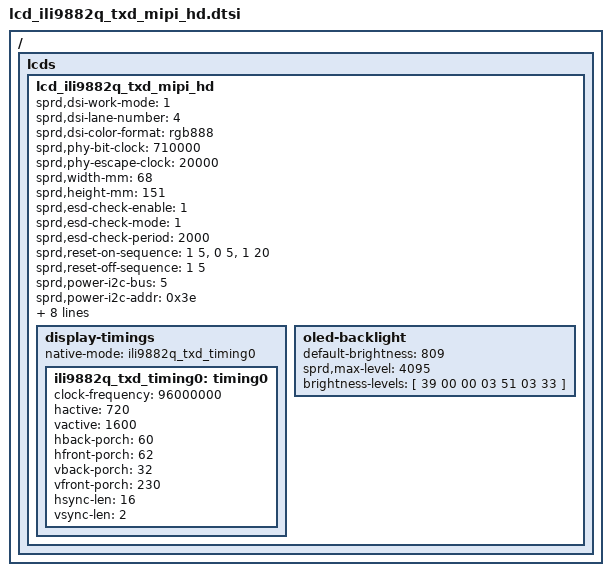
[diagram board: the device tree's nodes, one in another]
/ {
	fragment {
		target-path = "/";
		__overlay__ {
			lcds {
				lcd_ili9882q_txd_mipi_hd: lcd_ili9882q_txd_mipi_hd {
					sprd,dsi-work-mode = <1>; /* video burst mode*/
					sprd,dsi-lane-number = <4>;
					sprd,dsi-color-format = "rgb888";

					sprd,phy-bit-clock = <710000>;	/* kbps */
					sprd,phy-escape-clock = <20000>;/* kHz */

					sprd,width-mm = <68>;
					sprd,height-mm = <151>;

					sprd,esd-check-enable = <1>;
					sprd,esd-check-mode = <1>; /*1TE 0reg */
					sprd,esd-check-period = <2000>;
					/* sprd,esd-check-register = <0x0A>; */
					/* sprd,esd-check-value = <0x9C>; */

					sprd,reset-on-sequence = <1 5>, <0 5>, <1 20>;
					sprd,reset-off-sequence = <1 5>;

					sprd,power-i2c-bus = <5>;
					sprd,power-i2c-addr = <0x3e>;
					sprd,power-i2c-reg = [00 01 03];
					sprd,power-i2c-val = [14 14 03];

					/* sprd,use-dcs-write;*/
					sprd,initial-command = [
						39 00 00 04 FF 98 82 01
						39 00 00 02 00 44
						39 00 00 02 01 13
						39 00 00 02 02 10
						39 00 00 02 03 20
						39 00 00 02 04 CA
						39 00 00 02 05 13
						39 00 00 02 06 10
						39 00 00 02 07 20
						39 00 00 02 08 82
						39 00 00 02 09 09
						39 00 00 02 0a b3
						39 00 00 02 0b 00
						39 00 00 02 0c 17
						39 00 00 02 0d 17
						39 00 00 02 0e 04
						39 00 00 02 0f 04
						39 00 00 02 10 0A
						39 00 00 02 11 0A
						39 00 00 02 12 09
						39 00 00 02 1E 0A
						39 00 00 02 1F 0A
						39 00 00 02 16 82
						39 00 00 02 17 09
						39 00 00 02 18 33
						39 00 00 02 19 00
						39 00 00 02 1a 17
						39 00 00 02 1b 17
						39 00 00 02 1c 04
						39 00 00 02 1d 04
						39 00 00 02 20 09
						39 00 00 02 24 02
						39 00 00 02 25 0b
						39 00 00 02 26 10
						39 00 00 02 27 20
						39 00 00 02 2c 34
						39 00 00 02 31 07
						39 00 00 02 32 2a
						39 00 00 02 33 2a
						39 00 00 02 34 0D
						39 00 00 02 35 28
						39 00 00 02 36 29
						39 00 00 02 37 11
						39 00 00 02 38 13
						39 00 00 02 39 15
						39 00 00 02 3a 17
						39 00 00 02 3b 19
						39 00 00 02 3c 1b
						39 00 00 02 3d 09
						39 00 00 02 3e 07
						39 00 00 02 3f 07
						39 00 00 02 40 07
						39 00 00 02 41 07
						39 00 00 02 42 07
						39 00 00 02 43 07
						39 00 00 02 44 07
						39 00 00 02 45 07
						39 00 00 02 46 07
						39 00 00 02 47 07
						39 00 00 02 48 2a
						39 00 00 02 49 2a
						39 00 00 02 4a 0C
						39 00 00 02 4b 28
						39 00 00 02 4c 29
						39 00 00 02 4d 10
						39 00 00 02 4e 12
						39 00 00 02 4f 14
						39 00 00 02 50 16
						39 00 00 02 51 18
						39 00 00 02 52 1a
						39 00 00 02 53 08
						39 00 00 02 54 07
						39 00 00 02 55 07
						39 00 00 02 56 07
						39 00 00 02 57 07
						39 00 00 02 58 07
						39 00 00 02 59 07
						39 00 00 02 5a 07
						39 00 00 02 5b 07
						39 00 00 02 5c 07
						39 00 00 02 61 07
						39 00 00 02 62 2a
						39 00 00 02 63 2a
						39 00 00 02 64 0D
						39 00 00 02 65 28
						39 00 00 02 66 29
						39 00 00 02 67 11
						39 00 00 02 68 13
						39 00 00 02 69 15
						39 00 00 02 6a 17
						39 00 00 02 6b 19
						39 00 00 02 6c 1b
						39 00 00 02 6d 09
						39 00 00 02 6e 07
						39 00 00 02 6f 07
						39 00 00 02 70 07
						39 00 00 02 71 07
						39 00 00 02 72 07
						39 00 00 02 73 07
						39 00 00 02 74 07
						39 00 00 02 75 07
						39 00 00 02 76 07
						39 00 00 02 77 07
						39 00 00 02 78 2a
						39 00 00 02 79 2a
						39 00 00 02 7a 0C
						39 00 00 02 7b 28
						39 00 00 02 7c 29
						39 00 00 02 7d 10
						39 00 00 02 7e 12
						39 00 00 02 7f 14
						39 00 00 02 80 16
						39 00 00 02 81 18
						39 00 00 02 82 1a
						39 00 00 02 83 08
						39 00 00 02 84 07
						39 00 00 02 85 07
						39 00 00 02 86 07
						39 00 00 02 87 07
						39 00 00 02 88 07
						39 00 00 02 89 07
						39 00 00 02 8a 07
						39 00 00 02 8b 07
						39 00 00 02 8c 07
						39 00 00 02 A0 01
						39 00 00 02 A2 00
						39 00 00 02 A3 00
						39 00 00 02 A4 00
						39 00 00 02 A5 00
						39 00 00 02 A6 00
						39 00 00 02 A7 00
						39 00 00 02 A8 00
						39 00 00 02 A9 04
						39 00 00 02 AA 04
						39 00 00 02 AB 00
						39 00 00 02 AC 00
						39 00 00 02 AD 04
						39 00 00 02 AE 04
						39 00 00 02 B0 33
						39 00 00 02 B1 33
						39 00 00 02 B2 00
						39 00 00 02 B9 40
						39 00 00 02 C3 FF
						39 00 00 02 CA 44
						39 00 00 02 D0 01
						39 00 00 02 D1 00
						39 00 00 02 DC 37
						39 00 00 02 DD 42
						39 00 00 02 E2 00
						39 00 00 02 E6 23
						39 00 00 02 E7 54
						39 00 00 02 ED 00
						39 00 00 04 FF 98 82 02
						39 00 00 02 F1 1C
						39 00 00 02 4B 5A
						39 00 00 02 50 CA
						39 00 00 02 51 00
						39 00 00 02 06 8D
						39 00 00 02 0B A0
						39 00 00 02 0C 00
						39 00 00 02 0D 22
						39 00 00 02 0E E6
						39 00 00 02 4E 11
						39 00 00 02 4D CE
						39 00 00 02 F2 4A
						39 00 00 04 FF 98 82 05
						39 00 00 02 03 01
						39 00 00 02 04 13
						39 00 00 02 47 0A
						39 00 00 02 85 77
						39 00 00 02 63 9C
						39 00 00 02 64 9C
						39 00 00 02 68 8D
						39 00 00 02 69 93
						39 00 00 02 6A C9
						39 00 00 02 6B BB
						39 00 00 02 C8 8D
						39 00 00 02 C9 8D
						39 00 00 02 CA 8D
						39 00 00 02 CB 4D
						39 00 00 02 D0 93
						39 00 00 02 D1 93
						39 00 00 02 D2 93
						39 00 00 02 D3 53
						39 00 00 04 FF 98 82 03
						39 00 00 02 83 20
						39 00 00 02 84 00
						39 00 00 04 FF 98 82 06
						39 00 00 02 06 A4
						39 00 00 02 D9 1F
						39 00 00 02 C0 40
						39 00 00 02 C1 16
						39 00 00 02 80 09
						39 00 00 04 FF 98 82 07
						39 00 00 02 C0 01
						39 00 00 02 CB CF
						39 00 00 02 CC B0
						39 00 00 02 CD 9D
						39 00 00 02 CE 7E
						39 00 00 04 FF 98 82 08
						39 00 00 1C E0 00 24 52 76 A7 50 D3 F7 24 48 95 83 B4 E0 0A AA 36 6C 8F BC FE E2 15 54 89 03 EC
						39 00 00 1C E1 00 24 52 76 A7 50 D3 F7 24 48 95 83 B4 E0 0A AA 36 6C 8F BC FE E2 15 54 89 03 EC
						39 00 00 04 FF 98 82 0B
						39 00 00 02 9A 89
						39 00 00 02 9B 05
						39 00 00 02 9C 06
						39 00 00 02 9D 06
						39 00 00 02 9E E1
						39 00 00 02 9F E1
						39 00 00 02 AA 22
						39 00 00 02 AB E0
						39 00 00 02 AC 7F
						39 00 00 02 AD 3F
						39 00 00 04 FF 98 82 0E
						39 00 00 02 11 10
						39 00 00 02 12 08
						39 00 00 02 13 10
						39 00 00 02 00 A0
						39 00 00 04 FF 98 82 00
						39 00 00 03 51 00 00
						39 00 00 02 53 2C
						39 00 00 03 68 04 00
						39 00 00 02 35 00
						39 46 00 02 11 00
						39 05 00 02 29 00
						39 05 00 04 FF 98 82 0F
					];

					sprd,sleep-in-command = [
						39 05 00 04 FF 98 82 00
						05 14 00 01 28
						05 78 00 01 10
						];

					sprd,sleep-out-command = [
						05 78 00 01 11
						05 14 00 01 29
						15 00 00 02 26 01
						];
/*
					sprd,cabc-off-command = [
						23 00 00 02 55 00
						];
					sprd,cabc-ui-command = [
						23 00 00 02 55 01
						];
					sprd,cabc-still-image-command = [
						23 00 00 02 55 02
						];
					sprd,cabc-video-command = [
						23 00 00 02 55 03
						];

*/					display-timings {
						native-mode = <&ili9882q_txd_timing0>;
						ili9882q_txd_timing0: timing0 {
							clock-frequency = <96000000>;
							hactive = <720>;
							vactive = <1600>;
							hback-porch = <60>;
							hfront-porch = <62>;
							vback-porch = <32>;
							vfront-porch = <230>;
							hsync-len = <16>;
							vsync-len = <2>;
						};
					};

					oled-backlight {
						default-brightness = <809>;
						sprd,max-level = <4095>;
						brightness-levels = [
							39 00 00 03 51 03 33
						];
					};
				};
			};
		};
	};
};
